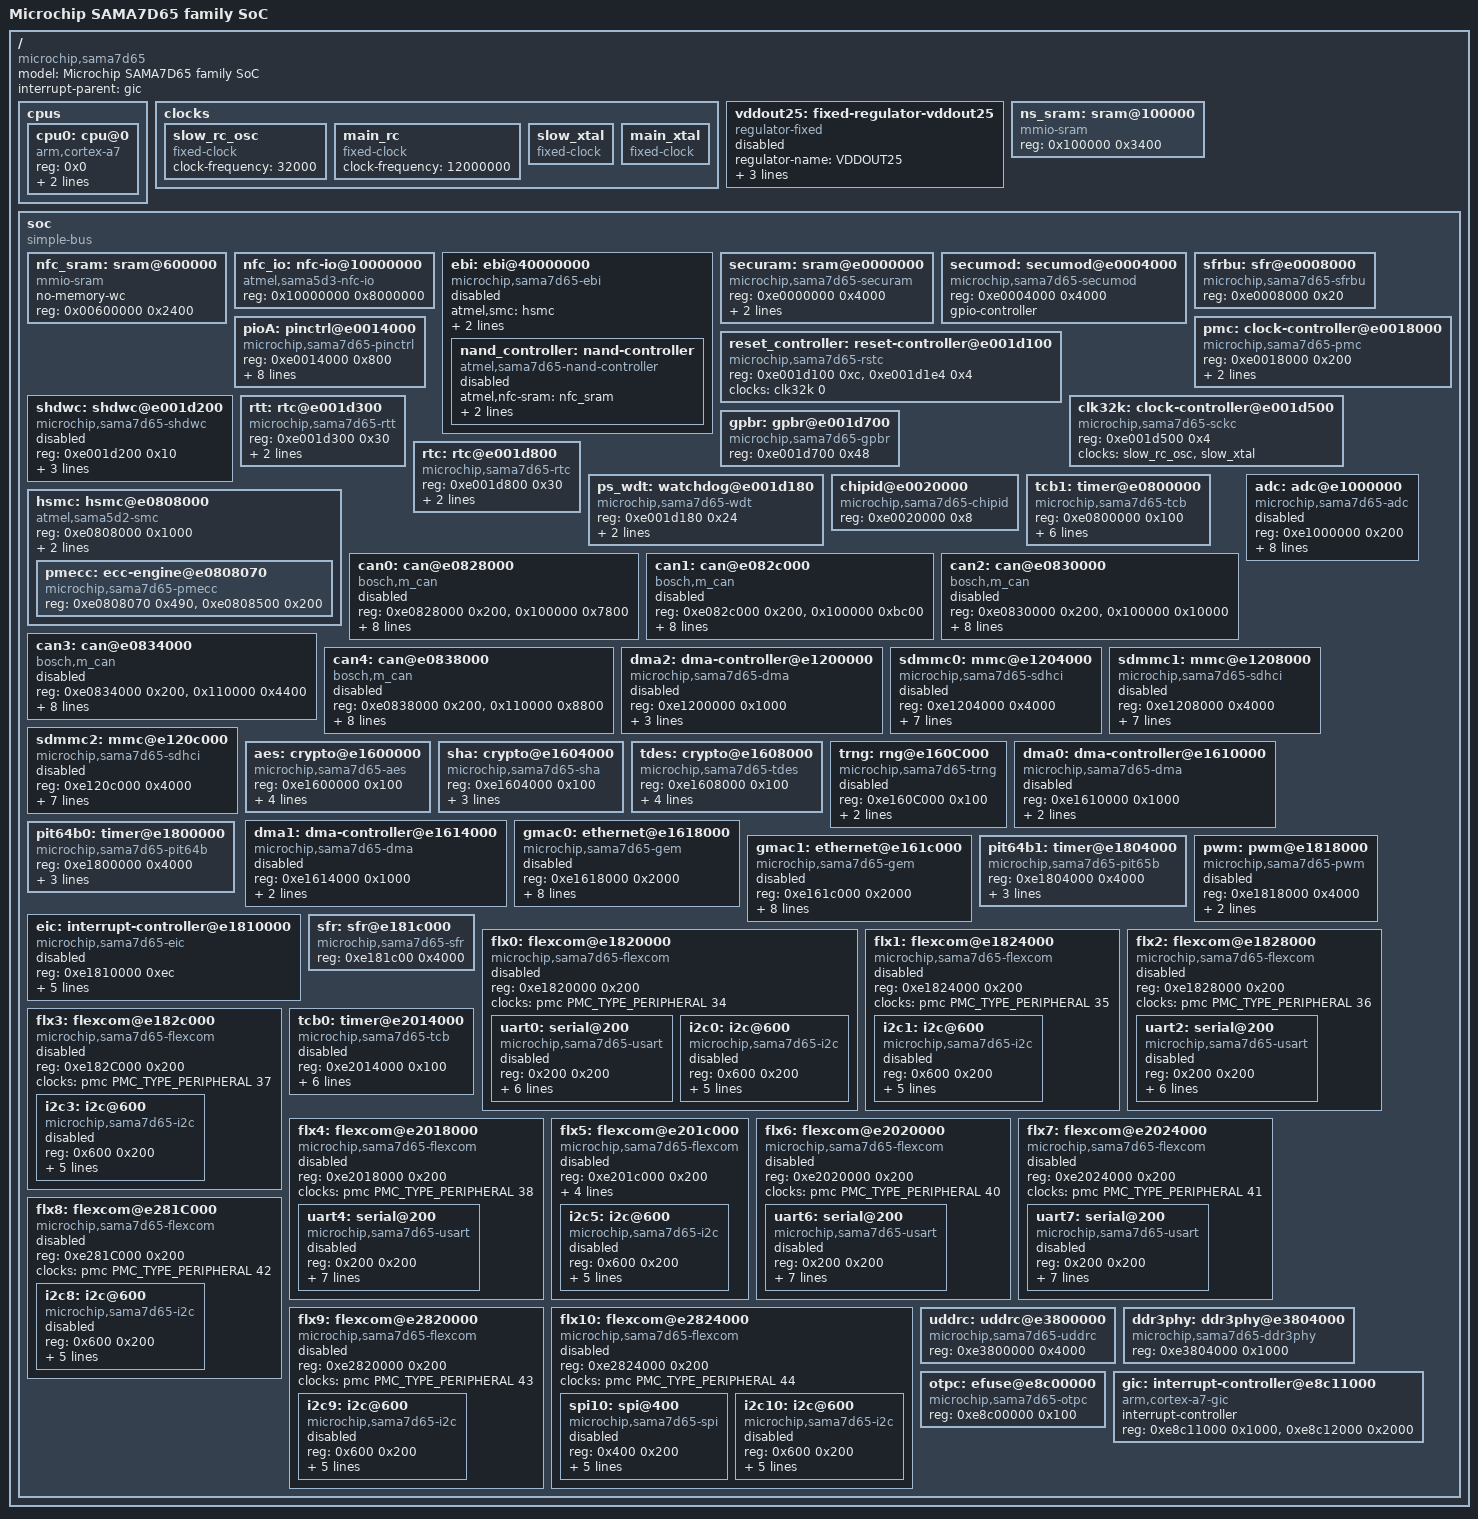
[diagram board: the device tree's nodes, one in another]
// SPDX-License-Identifier: (GPL-2.0+ OR MIT)
/*
 *  sama7d6.dtsi - Device Tree Include file for SAMA7D6 family SoC
 *
 *  Copyright (C) 2023 Microchip Technology, Inc. and its subsidiaries
 *
 *
 */

#include <dt-bindings/interrupt-controller/irq.h>
#include <dt-bindings/interrupt-controller/arm-gic.h>
#include <dt-bindings/clk/at91.h>
#include <dt-bindings/dma/at91.h>
#include <dt-bindings/gpio/gpio.h>

/ {
	model = "Microchip SAMA7D65 family SoC";
	compatible = "microchip,sama7d65";
	#address-cells = <1>;
	#size-cells = <1>;
	interrupt-parent = <&gic>;

	cpus {
		#address-cells = <1>;
		#size-cells = <0>;

		cpu0: cpu@0 {
			device_type = "cpu";
			compatible = "arm,cortex-a7";
			reg = <0x0>;
			clocks = <&pmc PMC_TYPE_CORE 8>, <&pmc PMC_TYPE_CORE 26>, <&main_xtal>;
			clock-names = "cpu", "master", "xtal";
		};
	};


	clocks {
		slow_rc_osc: slow_rc_osc {
			compatible = "fixed-clock";
			#clock-cells = <0>;
			clock-frequency = <32000>;
		};

		main_rc: main_rc {
			compatible = "fixed-clock";
			#clock-cells = <0>;
			clock-frequency = <12000000>;
		};

		slow_xtal: slow_xtal {
			compatible = "fixed-clock";
			#clock-cells = <0>;
		};

		main_xtal: main_xtal {
			compatible = "fixed-clock";
			#clock-cells = <0>;
		};
	};

	vddout25: fixed-regulator-vddout25 {
		compatible = "regulator-fixed";

		regulator-name = "VDDOUT25";
		regulator-min-microvolt = <2500000>;
		regulator-max-microvolt = <2500000>;
		regulator-boot-on;
		status = "disabled";
	};

	ns_sram: sram@100000 {
		compatible = "mmio-sram";
		#address-cells = <1>;
		#size-cells = <1>;
		reg = <0x100000 0x3400>;
		ranges;
	};

	soc {
		compatible = "simple-bus";
		#address-cells = <1>;
		#size-cells = <1>;
		ranges;

		nfc_sram: sram@600000 {
			compatible = "mmio-sram";
			no-memory-wc;
			reg = <0x00600000 0x2400>;
			#address-cells = <1>;
			#size-cells = <1>;
			ranges = <0 0x00600000 0x2400>;
		};

		nfc_io: nfc-io@10000000 {
			compatible = "atmel,sama5d3-nfc-io", "syscon";
			reg = <0x10000000 0x8000000>;
		};

		ebi: ebi@40000000 {
			compatible = "microchip,sama7d65-ebi", "atmel,sama5d3-ebi";
			#address-cells = <2>;
			#size-cells = <1>;
			atmel,smc = <&hsmc>;
			reg = <0x40000000 0x18000000>;
			ranges = <0x0 0x0 0x40000000 0x8000000
				  0x1 0x0 0x48000000 0x10000000>;
			clocks = <&pmc PMC_TYPE_CORE 31>; /* PMC_MCK5 */
			status = "disabled";

			nand_controller: nand-controller {
				compatible = "atmel,sama7d65-nand-controller", "atmel,sama5d3-nand-controller";
				atmel,nfc-sram = <&nfc_sram>;
				atmel,nfc-io = <&nfc_io>;
				ecc-engine = <&pmecc>;
				#address-cells = <2>;
				#size-cells = <1>;
				ranges;
				status = "disabled";
			};
		};

		securam: sram@e0000000 {
			compatible = "microchip,sama7d65-securam", "atmel,sama5d2-securam", "mmio-sram";
			reg = <0xe0000000 0x4000>;
			clocks = <&pmc PMC_TYPE_PERIPHERAL 17>;
			#address-cells = <1>;
			#size-cells = <1>;
			ranges = <0 0xe0000000 0x4000>;
			no-memory-wc;
		};

		secumod: secumod@e0004000 {
			compatible = "microchip,sama7d65-secumod", "atmel,sama5d2-secumod", "syscon";
			reg = <0xe0004000 0x4000>;
			gpio-controller;
			#gpio-cells = <2>;
		};

		sfrbu: sfr@e0008000 {
			compatible ="microchip,sama7d65-sfrbu", "atmel,sama5d2-sfrbu", "syscon";
			reg = <0xe0008000 0x20>;
		};

		pioA: pinctrl@e0014000 {
			compatible = "microchip,sama7d65-pinctrl", "microchip,sama7g5-pinctrl";
			reg = <0xe0014000 0x800>;
			interrupts = <GIC_SPI 10 IRQ_TYPE_LEVEL_HIGH>,
				<GIC_SPI 11 IRQ_TYPE_LEVEL_HIGH>,
				<GIC_SPI 12 IRQ_TYPE_LEVEL_HIGH>,
				<GIC_SPI 13 IRQ_TYPE_LEVEL_HIGH>,
				<GIC_SPI 14 IRQ_TYPE_LEVEL_HIGH>;
			clocks = <&pmc PMC_TYPE_PERIPHERAL 10>;
			interrupt-controller;
			#interrupt-cells = <2>;
			gpio-controller;
			#gpio-cells = <2>;
		};

		pmc: clock-controller@e0018000 {
			compatible = "microchip,sama7d65-pmc", "syscon";
			reg = <0xe0018000 0x200>;
			interrupts = <GIC_SPI 9 IRQ_TYPE_LEVEL_HIGH>;
			#clock-cells = <2>;
			clocks = <&clk32k 1>, <&clk32k 0>, <&main_xtal>, <&main_rc>;
			clock-names = "td_slck", "md_slck", "main_xtal", "main_rc";
		};

		reset_controller: reset-controller@e001d100 {
			compatible = "microchip,sama7d65-rstc", "microchip,sama7g5-rstc", "microchip,sam9x60-rstc";
			reg = <0xe001d100 0xc>, <0xe001d1e4 0x4>;
			#reset-cells = <1>;
			clocks = <&clk32k 0>;
		};

		shdwc: shdwc@e001d200 {
			compatible = "microchip,sama7d65-shdwc", "microchip,sama7g5-shdwc", "syscon";
			reg = <0xe001d200 0x10>;
			clocks = <&clk32k 0>;
			#address-cells = <1>;
			#size-cells = <0>;
			atmel,wakeup-rtc-timer;
			atmel,wakeup-rtt-timer;
			status = "disabled";
		};

		rtt: rtc@e001d300 {
			compatible = "microchip,sama7d65-rtt", "microchip,sama7g5-rtt", "microchip,sam9x60-rtt", "atmel,at91sam9260-rtt";
			reg = <0xe001d300 0x30>;
			interrupts = <GIC_SPI 7 IRQ_TYPE_LEVEL_HIGH>;
			clocks = <&clk32k 0>;
		};

		clk32k: clock-controller@e001d500 {
			compatible = "microchip,sama7d65-sckc", "microchip,sam9x60-sckc";
			reg = <0xe001d500 0x4>;
			clocks = <&slow_rc_osc>, <&slow_xtal>;
			#clock-cells = <1>;
		};

		gpbr: gpbr@e001d700 {
			compatible = "microchip,sama7d65-gpbr", "syscon";
			reg = <0xe001d700 0x48>;
		};

		rtc: rtc@e001d800 {
			compatible = "microchip,sama7d65-rtc", "microchip,sama7g5-rtc", "microchip,sam9x60-rtc";
			reg = <0xe001d800 0x30>;
			interrupts = <GIC_SPI 6 IRQ_TYPE_LEVEL_HIGH>;
			clocks = <&clk32k 1>;
		};

		ps_wdt: watchdog@e001d180 {
			compatible = "microchip,sama7d65-wdt", "microchip,sama7g5-wdt";
			reg = <0xe001d180 0x24>;
			interrupts = <GIC_SPI 2 IRQ_TYPE_LEVEL_HIGH>;
			clocks = <&clk32k 0>;
		};

		chipid@e0020000 {
			compatible = "microchip,sama7d65-chipid";
			reg = <0xe0020000 0x8>;
		};

		tcb1: timer@e0800000 {
			compatible = "microchip,sama7d65-tcb", "atmel,sama5d2-tcb", "simple-mfd", "syscon";
			#address-cells = <1>;
			#size-cells = <0>;
			reg = <0xe0800000 0x100>;
			interrupts = <GIC_SPI 86 IRQ_TYPE_LEVEL_HIGH>, <GIC_SPI 87 IRQ_TYPE_LEVEL_HIGH>, <GIC_SPI 88 IRQ_TYPE_LEVEL_HIGH>;
			clocks = <&pmc PMC_TYPE_PERIPHERAL 86>, <&pmc PMC_TYPE_PERIPHERAL 87>, <&pmc PMC_TYPE_PERIPHERAL 88>, <&clk32k 1>;
			clock-names = "t0_clk", "t1_clk", "t2_clk", "slow_clk";
		};

		hsmc: hsmc@e0808000 {
			compatible = "atmel,sama5d2-smc", "syscon", "simple-mfd";
			reg = <0xe0808000 0x1000>;
			interrupts = <GIC_SPI 20 IRQ_TYPE_LEVEL_HIGH>;
			clocks = <&pmc PMC_TYPE_PERIPHERAL 20>;
			#address-cells = <1>;
			#size-cells = <1>;
			ranges;

			pmecc: ecc-engine@e0808070 {
				compatible = "microchip,sama7d65-pmecc", "atmel,sama5d2-pmecc";
				reg = <0xe0808070 0x490>,
				      <0xe0808500 0x200>;
			};
		};

		can0: can@e0828000 {
			compatible = "bosch,m_can";
			reg = <0xe0828000 0x200>, <0x100000 0x7800>;
			reg-names = "m_can", "message_ram";
			interrupts = <GIC_SPI 58 IRQ_TYPE_LEVEL_HIGH
				      GIC_SPI 114 IRQ_TYPE_LEVEL_HIGH>;
			interrupt-names = "int0", "int1";
			clocks = <&pmc PMC_TYPE_PERIPHERAL 58>, <&pmc PMC_TYPE_GCK 58>;
			clock-names = "hclk", "cclk";
			assigned-clocks = <&pmc PMC_TYPE_GCK 58>;
			assigned-clock-parents = <&pmc PMC_TYPE_CORE 10>; /* sys pll div */
			assigned-clock-rates = <40000000>;
			bosch,mram-cfg = <0x3400 0 0 64 0 0 32 32>;
			status = "disabled";
		};

		can1: can@e082c000 {
			compatible = "bosch,m_can";
			reg = <0xe082c000 0x200>, <0x100000 0xbc00>;
			reg-names = "m_can", "message_ram";
			interrupts = <GIC_SPI 59 IRQ_TYPE_LEVEL_HIGH
				      GIC_SPI 115 IRQ_TYPE_LEVEL_HIGH>;
			interrupt-names = "int0", "int1";
			clocks = <&pmc PMC_TYPE_PERIPHERAL 59>, <&pmc PMC_TYPE_GCK 59>;
			clock-names = "hclk", "cclk";
			assigned-clocks = <&pmc PMC_TYPE_GCK 59>;
			assigned-clock-parents = <&pmc PMC_TYPE_CORE 10>; /* sys pll div */
			assigned-clock-rates = <40000000>;
			bosch,mram-cfg = <0x7800 0 0 64 0 0 32 32>;
			status = "disabled";
		};

		can2: can@e0830000 {
			compatible = "bosch,m_can";
			reg = <0xe0830000 0x200>, <0x100000 0x10000>;
			reg-names = "m_can", "message_ram";
			interrupts = <GIC_SPI 60 IRQ_TYPE_LEVEL_HIGH
				      GIC_SPI 116 IRQ_TYPE_LEVEL_HIGH>;
			interrupt-names = "int0", "int1";
			clocks = <&pmc PMC_TYPE_PERIPHERAL 60>, <&pmc PMC_TYPE_GCK 60>;
			clock-names = "hclk", "cclk";
			assigned-clocks = <&pmc PMC_TYPE_GCK 60>;
			assigned-clock-parents = <&pmc PMC_TYPE_CORE 10>; /* sys pll div */
			assigned-clock-rates = <40000000>;
			bosch,mram-cfg = <0xbc00 0 0 64 0 0 32 32>;
			status = "disabled";
		};

		can3: can@e0834000 {
			compatible = "bosch,m_can";
			reg = <0xe0834000 0x200>, <0x110000 0x4400>;
			reg-names = "m_can", "message_ram";
			interrupts = <GIC_SPI 61 IRQ_TYPE_LEVEL_HIGH
				      GIC_SPI 117 IRQ_TYPE_LEVEL_HIGH>;
			interrupt-names = "int0", "int1";
			clocks = <&pmc PMC_TYPE_PERIPHERAL 61>, <&pmc PMC_TYPE_GCK 61>;
			clock-names = "hclk", "cclk";
			assigned-clocks = <&pmc PMC_TYPE_GCK 61>;
			assigned-clock-parents = <&pmc PMC_TYPE_CORE 10>; /* sys pll div */
			assigned-clock-rates = <40000000>;
			bosch,mram-cfg = <0x0 0 0 64 0 0 32 32>;
			status = "disabled";
		};

		can4: can@e0838000 {
			compatible = "bosch,m_can";
			reg = <0xe0838000 0x200>, <0x110000 0x8800>;
			reg-names = "m_can", "message_ram";
			interrupts = <GIC_SPI 62 IRQ_TYPE_LEVEL_HIGH
				      GIC_SPI 118 IRQ_TYPE_LEVEL_HIGH>;
			interrupt-names = "int0", "int1";
			clocks = <&pmc PMC_TYPE_PERIPHERAL 62>, <&pmc PMC_TYPE_GCK 62>;
			clock-names = "hclk", "cclk";
			assigned-clocks = <&pmc PMC_TYPE_GCK 62>;
			assigned-clock-parents = <&pmc PMC_TYPE_CORE 10>; /* sys pll div */
			assigned-clock-rates = <40000000>;
			bosch,mram-cfg = <0x4400 0 0 64 0 0 32 32>;
			status = "disabled";
		};

		adc: adc@e1000000 {
			compatible = "microchip,sama7d65-adc", "microchip,sama7g5-adc";
			reg = <0xe1000000 0x200>;
			interrupts = <GIC_SPI 25 IRQ_TYPE_LEVEL_HIGH>;
			clocks = <&pmc PMC_TYPE_GCK 25>;
			assigned-clocks = <&pmc PMC_TYPE_GCK 25>;
			assigned-clock-rates = <100000000>;
			clock-names = "adc_clk";
			dmas = <&dma0 AT91_XDMAC_DT_PERID(0)>;
			dma-names = "rx";
			atmel,min-sample-rate-hz = <200000>;
			atmel,max-sample-rate-hz = <20000000>;
			atmel,startup-time-ms = <4>;
			status = "disabled";
		};

		dma2: dma-controller@e1200000 {
			compatible = "microchip,sama7d65-dma", "microchip,sama7g5-dma";
			reg = <0xe1200000 0x1000>;
			interrupts = <GIC_SPI 111 IRQ_TYPE_LEVEL_HIGH>;
			#dma-cells = <1>;
			clocks = <&pmc PMC_TYPE_PERIPHERAL 23>;
			clock-names = "dma_clk";
			dma-requests = <0>;
			status = "disabled";
		};

		sdmmc0: mmc@e1204000 {
			compatible = "microchip,sama7d65-sdhci", "microchip,sama7g5-sdhci", "microchip,sam9x60-sdhci";
			reg = <0xe1204000 0x4000>;
			interrupts = <GIC_SPI 75 IRQ_TYPE_LEVEL_HIGH>;
			clocks = <&pmc PMC_TYPE_PERIPHERAL 75>, <&pmc PMC_TYPE_GCK 75>;
			clock-names = "hclock", "multclk";
			assigned-clocks = <&pmc PMC_TYPE_GCK 75>;
			assigned-clock-rates = <200000000>;
			assigned-clock-parents = <&pmc PMC_TYPE_CORE 10>; /* MCK1 div */
			microchip,sdcal-inverted;
			status = "disabled";
		};

		sdmmc1: mmc@e1208000 {
			compatible = "microchip,sama7d65-sdhci", "microchip,sama7g5-sdhci", "microchip,sam9x60-sdhci";
			reg = <0xe1208000 0x4000>;
			interrupts = <GIC_SPI 76 IRQ_TYPE_LEVEL_HIGH>;
			clocks = <&pmc PMC_TYPE_PERIPHERAL 76>, <&pmc PMC_TYPE_GCK 76>;
			clock-names = "hclock", "multclk";
			assigned-clocks = <&pmc PMC_TYPE_GCK 76>;
			assigned-clock-rates = <200000000>;
			assigned-clock-parents = <&pmc PMC_TYPE_CORE 27>; /* MCK1 div */
			microchip,sdcal-inverted;
			status = "disabled";
		};

		sdmmc2: mmc@e120c000 {
			compatible = "microchip,sama7d65-sdhci", "microchip,sama7g5-sdhci", "microchip,sam9x60-sdhci";
			reg = <0xe120c000 0x4000>;
			interrupts = <GIC_SPI 77 IRQ_TYPE_LEVEL_HIGH>;
			clocks = <&pmc PMC_TYPE_PERIPHERAL 77>, <&pmc PMC_TYPE_GCK 77>;
			clock-names = "hclock", "multclk";
			assigned-clock-parents = <&pmc PMC_TYPE_CORE 27>; /* MCK1 div */
			assigned-clocks = <&pmc PMC_TYPE_GCK 77>;
			assigned-clock-rates = <200000000>;
			microchip,sdcal-inverted;
			status = "disabled";
		};

		aes: crypto@e1600000 {
			compatible = "microchip,sama7d65-aes", "atmel,at91sam9g46-aes";
			reg = <0xe1600000 0x100>;
			interrupts = <GIC_SPI 26 IRQ_TYPE_LEVEL_HIGH>;
			clocks = <&pmc PMC_TYPE_PERIPHERAL 26>;
			clock-names = "aes_clk";
			dmas = <&dma0 AT91_XDMAC_DT_PERID(1)>,
			       <&dma0 AT91_XDMAC_DT_PERID(2)>;
			dma-names = "tx", "rx";
		};

		sha: crypto@e1604000 {
			compatible = "microchip,sama7d65-sha", "atmel,at91sam9g46-sha";
			reg = <0xe1604000 0x100>;
			interrupts = <GIC_SPI 78 IRQ_TYPE_LEVEL_HIGH>;
			clocks = <&pmc PMC_TYPE_PERIPHERAL 78>;
			clock-names = "sha_clk";
			dmas = <&dma0 AT91_XDMAC_DT_PERID(48)>;
			dma-names = "tx";
		};

		tdes: crypto@e1608000 {
			compatible = "microchip,sama7d65-tdes", "atmel,at91sam9g46-tdes";
			reg = <0xe1608000 0x100>;
			interrupts = <GIC_SPI 91 IRQ_TYPE_LEVEL_HIGH>;
			clocks = <&pmc PMC_TYPE_PERIPHERAL 91>;
			clock-names = "tdes_clk";
			dmas = <&dma0 AT91_XDMAC_DT_PERID(54)>,
			       <&dma0 AT91_XDMAC_DT_PERID(53)>;
			dma-names = "tx", "rx";
		};

		trng: rng@e160C000 {
			compatible = "microchip,sama7d65-trng", "atmel,at91sam9g45-trng";
			reg = <0xe160C000 0x100>;
			interrupts = <GIC_SPI 92 IRQ_TYPE_LEVEL_HIGH>;
			clocks = <&pmc PMC_TYPE_PERIPHERAL 92>;
			status = "disabled";
		};

		dma0: dma-controller@e1610000 {
			compatible = "microchip,sama7d65-dma", "microchip,sama7g5-dma";
			reg = < 0xe1610000 0x1000>;
			interrupts = <GIC_SPI 109 IRQ_TYPE_LEVEL_HIGH>;
			#dma-cells = <1>;
			clocks = <&pmc PMC_TYPE_PERIPHERAL 21>;
			clock-names = "dma_clk";
			status = "disabled";
		};

		dma1: dma-controller@e1614000 {
			compatible = "microchip,sama7d65-dma", "microchip,sama7g5-dma";
			reg = <0xe1614000 0x1000>;
			interrupts = <GIC_SPI 110 IRQ_TYPE_LEVEL_HIGH>;
			#dma-cells = <1>;
			clocks = <&pmc PMC_TYPE_PERIPHERAL 22>;
			clock-names = "dma_clk";
			status = "disabled";
		};

		gmac0: ethernet@e1618000 {
			compatible = "microchip,sama7d65-gem", "cdns,sama7g5-gem";
			reg = <0xe1618000 0x2000>;
			interrupts = <GIC_SPI 46 IRQ_TYPE_LEVEL_HIGH
				      GIC_SPI 144 IRQ_TYPE_LEVEL_HIGH
				      GIC_SPI 145 IRQ_TYPE_LEVEL_HIGH
				      GIC_SPI 146 IRQ_TYPE_LEVEL_HIGH
				      GIC_SPI 147 IRQ_TYPE_LEVEL_HIGH
				      GIC_SPI 148 IRQ_TYPE_LEVEL_HIGH>;
			clocks = <&pmc PMC_TYPE_PERIPHERAL 46>, <&pmc PMC_TYPE_PERIPHERAL 46>, <&pmc PMC_TYPE_GCK 46>, <&pmc PMC_TYPE_GCK 49>;
			clock-names = "pclk", "hclk", "tx_clk", "tsu_clk";
			assigned-clocks = <&pmc PMC_TYPE_GCK 46>;
			assigned-clock-rates = <125000000>;
			assigned-clock-parents = <&pmc PMC_TYPE_CORE 21>; /* eth pll div. */
			status = "disabled";
		};

		gmac1: ethernet@e161c000 {
			compatible = "microchip,sama7d65-gem", "cdns,sama7g5-gem";
			reg = <0xe161c000 0x2000>;
			interrupts = <GIC_SPI 47 IRQ_TYPE_LEVEL_HIGH
				      GIC_SPI 151 IRQ_TYPE_LEVEL_HIGH
				      GIC_SPI 152 IRQ_TYPE_LEVEL_HIGH
				      GIC_SPI 153 IRQ_TYPE_LEVEL_HIGH
				      GIC_SPI 154 IRQ_TYPE_LEVEL_HIGH
				      GIC_SPI 155 IRQ_TYPE_LEVEL_HIGH>;
			clocks = <&pmc PMC_TYPE_PERIPHERAL 47>, <&pmc PMC_TYPE_PERIPHERAL 47>,<&pmc PMC_TYPE_GCK 47>, <&pmc PMC_TYPE_GCK 50>;
			clock-names = "pclk", "hclk","tx_clk", "tsu_clk";
			assigned-clocks = <&pmc PMC_TYPE_GCK 47>;
			assigned-clock-rates = <125000000>;
			assigned-clock-parents = <&pmc PMC_TYPE_CORE 21>; /* eth pll div. */
			status = "disabled";
		};

		pit64b0: timer@e1800000 {
			compatible = "microchip,sama7d65-pit64b", "microchip,sam9x60-pit64b";
			reg = <0xe1800000 0x4000>;
			interrupts = <GIC_SPI 66 IRQ_TYPE_LEVEL_HIGH>;
			clocks = <&pmc PMC_TYPE_PERIPHERAL 66>, <&pmc PMC_TYPE_GCK 66>;
			clock-names = "pclk", "gclk";
		};

		pit64b1: timer@e1804000 {
			compatible = "microchip,sama7d65-pit65b", "microchip,sam9x60-pit64b";
			reg = <0xe1804000 0x4000>;
			interrupts = <GIC_SPI 67 IRQ_TYPE_LEVEL_HIGH>;
			clocks = <&pmc PMC_TYPE_PERIPHERAL 67>, <&pmc PMC_TYPE_GCK 67>;
			clock-names = "pclk", "gclk";
		};

		eic: interrupt-controller@e1810000 {
			compatible = "microchip,sama7d65-eic", "microchip,sama7g5-eic";
			reg = <0xe1810000 0xec>;
			interrupt-parent = <&gic>;
			interrupt-controller;
			#interrupt-cells = <2>;
			interrupts = <GIC_SPI 142 IRQ_TYPE_LEVEL_HIGH>,
				     <GIC_SPI 143 IRQ_TYPE_LEVEL_HIGH>;
			clocks = <&pmc PMC_TYPE_PERIPHERAL 33>;
			clock-names = "pclk";
			status = "disabled";
		};

		pwm: pwm@e1818000 {
			compatible = "microchip,sama7d65-pwm", "atmel,sama5d2-pwm";
			reg = <0xe1818000 0x4000>;
			interrupts = <GIC_SPI 72 IRQ_TYPE_LEVEL_HIGH>;
			#pwm-cells = <3>;
			clocks = <&pmc PMC_TYPE_PERIPHERAL 72>;
			status = "disabled";
		};

		sfr: sfr@e181c000 {
			compatible = "microchip,sama7d65-sfr", "microchip,sam9x60-sfr", "syscon";
			reg = <0xe181c00 0x4000>;
		};

		flx0: flexcom@e1820000 {
			compatible = "microchip,sama7d65-flexcom", "atmel,sama5d2-flexcom";
			reg = <0xe1820000 0x200>;
			clocks = <&pmc PMC_TYPE_PERIPHERAL 34>;
			#address-cells = <1>;
			#size-cells = <1>;
			ranges = <0x0 0xe1820000 0x800>;
			status = "disabled";

			uart0: serial@200 {
				compatible = "microchip,sama7d65-usart", "atmel,at91sam9260-usart";
				reg = <0x200 0x200>;
				interrupts = <GIC_SPI 34 IRQ_TYPE_LEVEL_HIGH>;
				clocks = <&pmc PMC_TYPE_PERIPHERAL 34>;
				clock-names = "usart";
				dmas = <&dma1 AT91_XDMAC_DT_PERID(6)>,
					<&dma1 AT91_XDMAC_DT_PERID(5)>;
				dma-names = "tx", "rx";
				atmel,use-dma-rx;
				atmel,use-dma-tx;
				status = "disabled";
			};

			i2c0: i2c@600 {
				compatible = "microchip,sama7d65-i2c", "microchip,sam9x60-i2c";
				reg = <0x600 0x200>;
				interrupts = <GIC_SPI 34 IRQ_TYPE_LEVEL_HIGH>;
				#address-cells = <1>;
				#size-cells = <0>;
				clocks = <&pmc PMC_TYPE_PERIPHERAL 34>;
				atmel,fifo-size = <32>;
				dmas = <&dma0 AT91_XDMAC_DT_PERID(6)>,
					<&dma0 AT91_XDMAC_DT_PERID(5)>;
				dma-names = "tx", "rx";
				status = "disabled";
			};
		};

		flx1: flexcom@e1824000 {
			compatible = "microchip,sama7d65-flexcom", "atmel,sama5d2-flexcom";
			reg = <0xe1824000 0x200>;
			clocks = <&pmc PMC_TYPE_PERIPHERAL 35>;
			#address-cells = <1>;
			#size-cells = <1>;
			ranges = <0x0 0xe1824000 0x800>;
			status = "disabled";

			i2c1: i2c@600 {
				compatible = "microchip,sama7d65-i2c", "microchip,sam9x60-i2c";
				reg = <0x600 0x200>;
				interrupts = <GIC_SPI 35 IRQ_TYPE_LEVEL_HIGH>;
				#address-cells = <1>;
				#size-cells = <0>;
				clocks = <&pmc PMC_TYPE_PERIPHERAL 35>;
				atmel,fifo-size = <32>;
				dmas = <&dma0 AT91_XDMAC_DT_PERID(8)>,
					<&dma0 AT91_XDMAC_DT_PERID(7)>;
				dma-names = "tx", "rx";
				status = "disabled";
			};
		};

		flx2: flexcom@e1828000 {
			compatible = "microchip,sama7d65-flexcom", "atmel,sama5d2-flexcom";
			reg = <0xe1828000 0x200>;
			clocks = <&pmc PMC_TYPE_PERIPHERAL 36>;
			#address-cells = <1>;
			#size-cells = <1>;
			ranges = <0x0 0xe1828000 0x800>;
			status = "disabled";

			uart2: serial@200 {
				compatible = "microchip,sama7d65-usart", "atmel,at91sam9260-usart";
				reg = <0x200 0x200>;
				interrupts = <GIC_SPI 36 IRQ_TYPE_LEVEL_HIGH>;
				clocks = <&pmc PMC_TYPE_PERIPHERAL 36>;
				clock-names = "usart";
				dmas = <&dma1 AT91_XDMAC_DT_PERID(10)>,
					<&dma1 AT91_XDMAC_DT_PERID(9)>;
				dma-names = "tx", "rx";
				atmel,use-dma-rx;
				atmel,use-dma-tx;
				status = "disabled";
			};
		};

		flx3: flexcom@e182c000 {
			compatible = "microchip,sama7d65-flexcom", "atmel,sama5d2-flexcom";
			reg = <0xe182C000 0x200>;
			clocks = <&pmc PMC_TYPE_PERIPHERAL 37>;
			#address-cells = <1>;
			#size-cells = <1>;
			ranges = <0x0 0xe182c000 0x800>;
			status = "disabled";

			i2c3: i2c@600 {
				compatible = "microchip,sama7d65-i2c", "microchip,sam9x60-i2c";
				reg = <0x600 0x200>;
				interrupts = <GIC_SPI 37 IRQ_TYPE_LEVEL_HIGH>;
				#address-cells = <1>;
				#size-cells = <0>;
				clocks = <&pmc PMC_TYPE_PERIPHERAL 37>;
				atmel,fifo-size = <32>;
				dmas = <&dma0 AT91_XDMAC_DT_PERID(12)>,
						<&dma0 AT91_XDMAC_DT_PERID(11)>;
				dma-names = "tx", "rx";
				status = "disabled";
			};

		};

		tcb0: timer@e2014000{
			compatible = "microchip,sama7d65-tcb", "atmel,sama5d2-tcb", "simple-mfd", "syscon";
			#address-cells = <1>;
			#size-cells = <0>;
			reg = <0xe2014000 0x100>;
			interrupts = <GIC_SPI 83 IRQ_TYPE_LEVEL_HIGH>, <GIC_SPI 84 IRQ_TYPE_LEVEL_HIGH>, <GIC_SPI 85 IRQ_TYPE_LEVEL_HIGH>;
			clocks = <&pmc PMC_TYPE_PERIPHERAL 83>, <&pmc PMC_TYPE_PERIPHERAL 84>, <&pmc PMC_TYPE_PERIPHERAL 85>, <&clk32k 1>;
			clock-names = "t0_clk", "t1_clk", "t2_clk", "slow_clk";
			status = "disabled";
		};

		flx4: flexcom@e2018000 {
			compatible = "microchip,sama7d65-flexcom", "atmel,sama5d2-flexcom";
			reg = <0xe2018000 0x200>;
			clocks = <&pmc PMC_TYPE_PERIPHERAL 38>;
			#address-cells = <1>;
			#size-cells = <1>;
			ranges = <0x0 0xe2018000 0x800>;
			status = "disabled";

			uart4: serial@200 {
				compatible = "microchip,sama7d65-usart", "atmel,at91sam9260-usart";
				reg = <0x200 0x200>;
				interrupts = <GIC_SPI 38 IRQ_TYPE_LEVEL_HIGH>;
				clocks = <&pmc PMC_TYPE_PERIPHERAL 38>;
				clock-names = "usart";
				dmas = <&dma1 AT91_XDMAC_DT_PERID(14)>,
					<&dma1 AT91_XDMAC_DT_PERID(13)>;
				dma-names = "tx", "rx";
				atmel,use-dma-rx;
				atmel,use-dma-tx;
				atmel,fifo-size = <16>;
				status = "disabled";
			};
		};

		flx5: flexcom@e201c000 {
			compatible = "microchip,sama7d65-flexcom", "atmel,sama5d2-flexcom";
			reg = <0xe201c000 0x200>;
			clocks = <&pmc PMC_TYPE_PERIPHERAL 39>;
			#address-cells = <1>;
			#size-cells = <1>;
			ranges = <0x0 0xe201c000 0x800>;
			assigned-clock-parents = <&pmc PMC_TYPE_CORE 16>;
			assigned-clocks = <&pmc PMC_TYPE_GCK 39>;
			assigned-clock-rates = <34000000>;
			status = "disabled";

			i2c5: i2c@600 {
				compatible = "microchip,sama7d65-i2c", "microchip,sam9x60-i2c";
				reg = <0x600 0x200>;
				interrupts = <GIC_SPI 39 IRQ_TYPE_LEVEL_HIGH>;
				#address-cells = <1>;
				#size-cells = <0>;
				clocks = <&pmc PMC_TYPE_PERIPHERAL 39>;
				atmel,fifo-size = <32>;
				dmas = <&dma0 AT91_XDMAC_DT_PERID(16)>,
						<&dma0 AT91_XDMAC_DT_PERID(15)>;
				dma-names = "tx", "rx";
				status = "disabled";
			};
		};

		flx6: flexcom@e2020000 {
			compatible = "microchip,sama7d65-flexcom", "atmel,sama5d2-flexcom";
			reg = <0xe2020000 0x200>;
			clocks = <&pmc PMC_TYPE_PERIPHERAL 40>;
			#address-cells = <1>;
			#size-cells = <1>;
			ranges = <0x0 0xe2020000 0x800>;
			status = "disabled";

			uart6: serial@200 {
				compatible = "microchip,sama7d65-usart", "atmel,at91sam9260-usart";
				reg = <0x200 0x200>;
				interrupts = <GIC_SPI 40 IRQ_TYPE_LEVEL_HIGH>;
				clocks = <&pmc PMC_TYPE_PERIPHERAL 40>;
				clock-names = "usart";
				dmas = <&dma1 AT91_XDMAC_DT_PERID(18)>,
					<&dma1 AT91_XDMAC_DT_PERID(17)>;
				dma-names = "tx", "rx";
				atmel,use-dma-rx;
				atmel,use-dma-tx;
				atmel,fifo-size = <16>;
				status = "disabled";
			};
		};

		flx7: flexcom@e2024000 {
			compatible = "microchip,sama7d65-flexcom", "atmel,sama5d2-flexcom";
			reg = <0xe2024000 0x200>;
			clocks = <&pmc PMC_TYPE_PERIPHERAL 41>;
			#address-cells = <1>;
			#size-cells = <1>;
			ranges = <0x0 0xe2024000 0x800>;
			status = "disabled";

			uart7: serial@200 {
				compatible = "microchip,sama7d65-usart", "atmel,at91sam9260-usart";
				reg = <0x200 0x200>;
				interrupts = <GIC_SPI 41 IRQ_TYPE_LEVEL_HIGH>;
				clocks = <&pmc PMC_TYPE_PERIPHERAL 41>;
				clock-names = "usart";
				dmas = <&dma1 AT91_XDMAC_DT_PERID(20)>,
					<&dma1 AT91_XDMAC_DT_PERID(19)>;
				dma-names = "tx", "rx";
				atmel,use-dma-rx;
				atmel,use-dma-tx;
				atmel,fifo-size = <16>;
				status = "disabled";
			};
		};

		flx8: flexcom@e281C000{
			compatible = "microchip,sama7d65-flexcom", "atmel,sama5d2-flexcom";
			reg = <0xe281C000 0x200>;
			clocks = <&pmc PMC_TYPE_PERIPHERAL 42>;
			#address-cells = <1>;
			#size-cells = <1>;
			ranges = <0x0 0xe281C000 0x800>;
			status = "disabled";

			i2c8: i2c@600 {
				compatible = "microchip,sama7d65-i2c", "microchip,sam9x60-i2c";
				reg = <0x600 0x200>;
				interrupts = <GIC_SPI 42 IRQ_TYPE_LEVEL_HIGH>;
				#address-cells = <1>;
				#size-cells = <0>;
				clocks = <&pmc PMC_TYPE_PERIPHERAL 42>;
				atmel,fifo-size = <32>;
				dmas = <&dma0 AT91_XDMAC_DT_PERID(22)>,
					<&dma0 AT91_XDMAC_DT_PERID(21)>;
				dma-names = "tx", "rx";
				status = "disabled";
			};
		};

		flx9: flexcom@e2820000 {
			compatible = "microchip,sama7d65-flexcom", "atmel,sama5d2-flexcom";
			reg = <0xe2820000 0x200>;
			clocks = <&pmc PMC_TYPE_PERIPHERAL 43>;
			#address-cells = <1>;
			#size-cells = <1>;
			ranges = <0x0 0xe281c000 0x800>;
			status = "disabled";

			i2c9: i2c@600 {
				compatible = "microchip,sama7d65-i2c", "microchip,sam9x60-i2c";
				reg = <0x600 0x200>;
				interrupts = <GIC_SPI 43 IRQ_TYPE_LEVEL_HIGH>;
				#address-cells = <1>;
				#size-cells = <0>;
				clocks = <&pmc PMC_TYPE_PERIPHERAL 43>;
				atmel,fifo-size = <32>;
				dmas = <&dma0 AT91_XDMAC_DT_PERID(24)>,
					<&dma0 AT91_XDMAC_DT_PERID(23)>;
				dma-names = "tx", "rx";
				status = "disabled";
			};
		};

		flx10: flexcom@e2824000 {
			compatible = "microchip,sama7d65-flexcom", "atmel,sama5d2-flexcom";
			reg = <0xe2824000 0x200>;
			clocks = <&pmc PMC_TYPE_PERIPHERAL 44>;
			#address-cells = <1>;
			#size-cells = <1>;
			ranges = <0x0 0xe2824000 0x800>;
			status = "disabled";

			spi10: spi@400 {
				compatible = "microchip,sama7d65-spi", "atmel,at91rm9200-spi";
				reg = <0x400 0x200>;
				interrupts = <GIC_SPI 44 IRQ_TYPE_LEVEL_HIGH>;
				clocks = <&pmc PMC_TYPE_PERIPHERAL 44>;
				clock-names = "spi_clk";
				#address-cells = <1>;
				#size-cells = <0>;
				atmel,fifo-size = <32>;
				dmas = <&dma0 AT91_XDMAC_DT_PERID(25)>,
					    <&dma0 AT91_XDMAC_DT_PERID(26)>;
				dma-names = "tx", "rx";
				status = "disabled";
			};

			i2c10: i2c@600 {
				compatible = "microchip,sama7d65-i2c", "microchip,sam9x60-i2c";
				reg = <0x600 0x200>;
				interrupts = <GIC_SPI 44 IRQ_TYPE_LEVEL_HIGH>;
				#address-cells = <1>;
				#size-cells = <0>;
				clocks = <&pmc PMC_TYPE_PERIPHERAL 44>;
				atmel,fifo-size = <32>;
				dmas = <&dma0 AT91_XDMAC_DT_PERID(26)>,
					<&dma0 AT91_XDMAC_DT_PERID(25)>;
				dma-names = "tx", "rx";
				status = "disabled";
			};
		};

		uddrc: uddrc@e3800000 {
			compatible = "microchip,sama7d65-uddrc", "microchip,sama7g5-uddrc";
			reg = <0xe3800000 0x4000>;
		};

		ddr3phy: ddr3phy@e3804000 {
			compatible = "microchip,sama7d65-ddr3phy", "microchip,sama7g5-ddr3phy";
			reg = <0xe3804000 0x1000>;
		};

		otpc: efuse@e8c00000 {
			compatible = "microchip,sama7d65-otpc", "microchip,sama7g5-otpc", "syscon";
			reg = <0xe8c00000 0x100>;
			#address-cells = <1>;
			#size-cells = <1>;
		};

		gic: interrupt-controller@e8c11000 {
			compatible = "arm,cortex-a7-gic";
			#interrupt-cells = <3>;
			#address-cells = <0>;
			interrupt-controller;
			reg = <0xe8c11000 0x1000>,
				<0xe8c12000 0x2000>;
		};
	};
};
